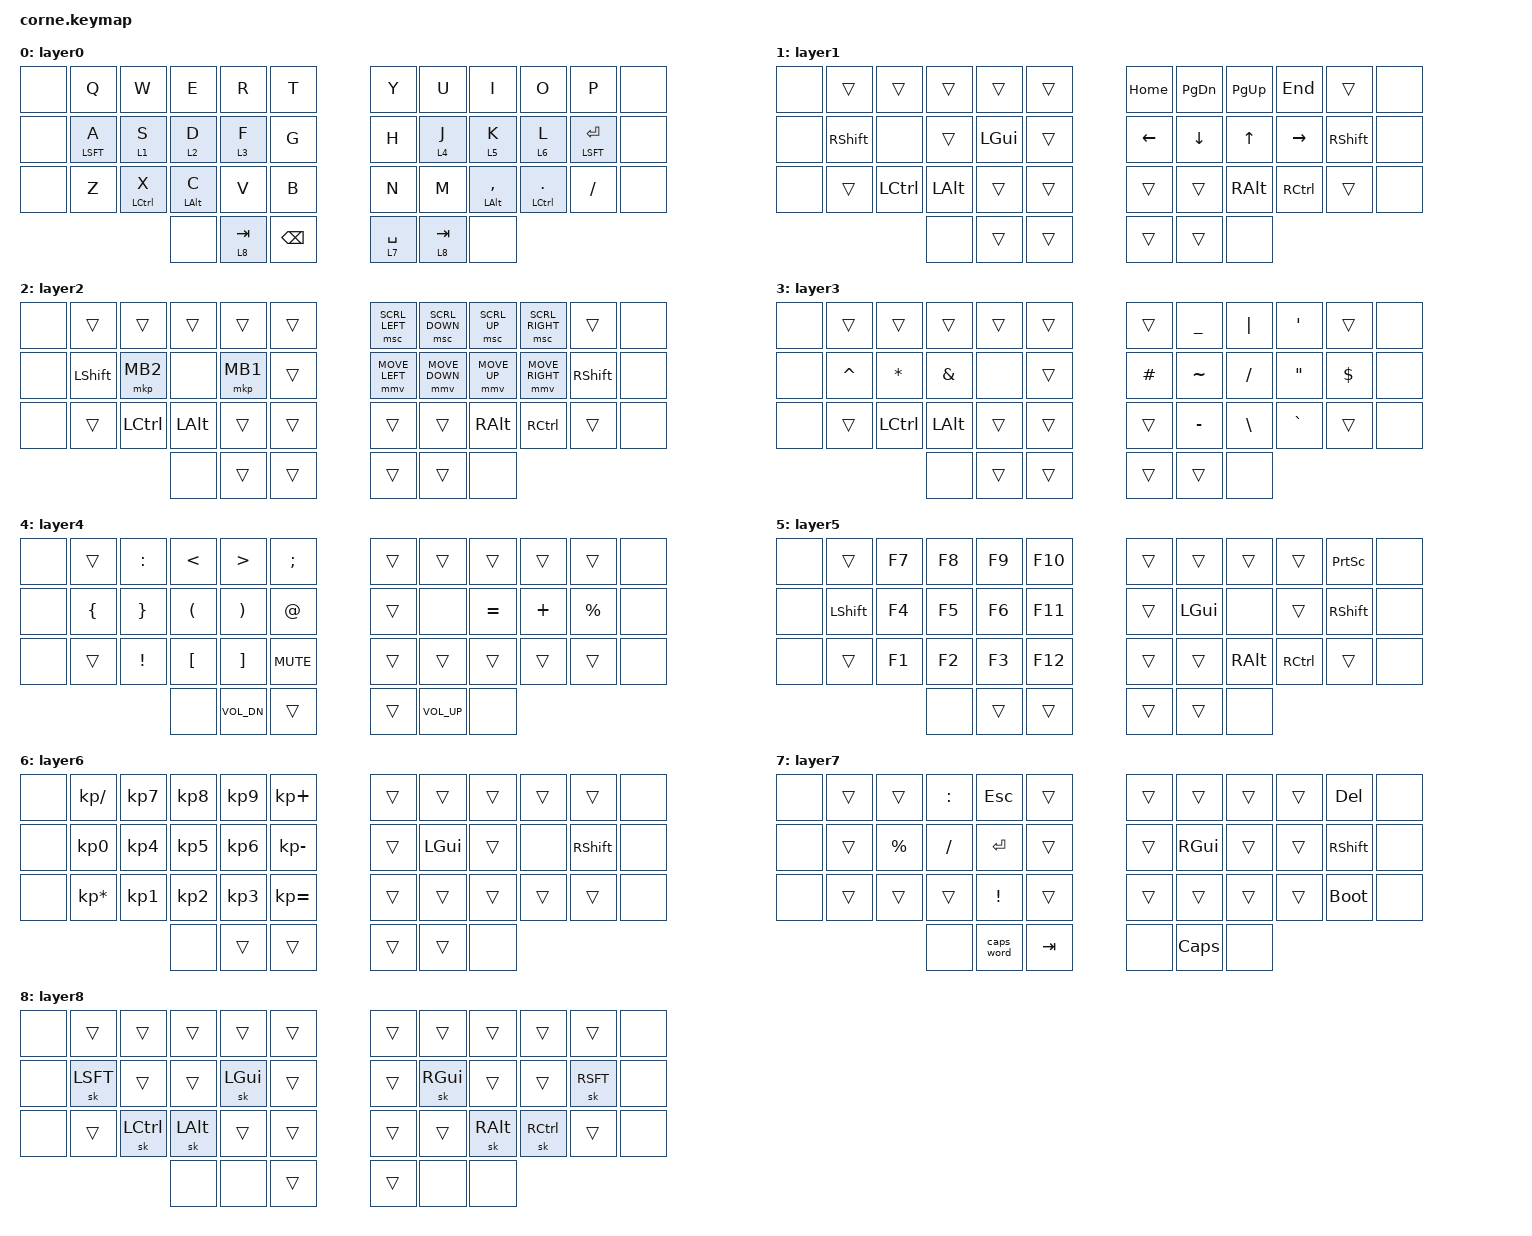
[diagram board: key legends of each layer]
/*
 * Copyright (c) 2020 The ZMK Contributors
 *
 * SPDX-License-Identifier: MIT
 */

#include <behaviors.dtsi>
#include <dt-bindings/zmk/keys.h>
#include <dt-bindings/zmk/bt.h>

#include <dt-bindings/zmk/pointing.h>


/ {
        behaviors {
                ht_bl: balanced_homerow_mods {
                        compatible = "zmk,behavior-hold-tap";
                        #binding-cells = <2>;
                        tapping-term-ms = <200>;    // <---[[moderate duration]]
                        quick-tap-ms = <0>;
                        flavor = "balanced";
                        bindings = <&kp>, <&kp>;

                };
        };
        keymap {
                compatible = "zmk,keymap";
        layer0 {
                bindings = <
&none           &kp Q           &kp W           &kp E           &kp R           &kp T           &kp Y           &kp U           &kp I           &kp O           &kp P           &none
&none           &ht_bl LSFT A   &lt 1 S         &lt 2 D         &lt 3 F         &kp G           &kp H           &lt 4 J         &lt 5 K         &lt 6 L         &ht_bl LSFT ENTER&none
&none           &kp Z           &ht_bl LCTL X   &mt LALT C      &kp V           &kp B           &kp N           &kp M           &mt LALT COMMA  &ht_bl LCTL DOT &kp FSLH        &none
                                                &none           &lt 8 TAB       &kp BSPC        &lt 7 SPC       &lt 8 TAB       &none
                >;
        };
        layer1 {
                bindings = <
&none           &trans          &trans          &trans          &trans          &trans          &kp HOME        &kp PG_DN       &kp PG_UP       &kp END         &trans          &none
&none           &kp RSHFT       &none           &trans          &kp LGUI        &trans          &kp LEFT        &kp DOWN        &kp UP          &kp RIGHT       &kp RSHFT       &none
&none           &trans          &kp LCTL        &kp LALT        &trans          &trans          &trans          &trans          &kp RALT        &kp RCTL        &trans          &none
                                                &none           &trans          &trans          &trans          &trans          &none
                >;
        };
        layer2 {
                bindings = <
&none           &trans          &trans          &trans          &trans          &trans          &msc SCRL_LEFT  &msc SCRL_DOWN  &msc SCRL_UP    &msc SCRL_RIGHT &trans          &none
&none           &kp LSHFT       &mkp MB2        &none           &mkp MB1        &trans          &mmv MOVE_LEFT  &mmv MOVE_DOWN  &mmv MOVE_UP    &mmv MOVE_RIGHT &kp RSHFT       &none
&none           &trans          &kp LCTL        &kp LALT        &trans          &trans          &trans          &trans          &kp RALT        &kp RCTL        &trans          &none
                                                &none           &trans          &trans          &trans          &trans          &none
                >;
        };
        layer3 {
                bindings = <
&none           &trans          &trans          &trans          &trans          &trans          &trans          &kp UNDER       &kp PIPE        &kp SQT         &trans          &none
&none           &kp CARET       &kp STAR        &kp AMPS        &none           &trans          &kp HASH        &kp TILDE       &kp FSLH        &kp DQT         &kp DLLR        &none
&none           &trans          &kp LCTL        &kp LALT        &trans          &trans          &trans          &kp MINUS       &kp BSLH        &kp GRAVE       &trans          &none
                                                &none           &trans          &trans          &trans          &trans          &none
                >;
        };
        layer4 {
                bindings = <
&none           &trans          &kp COLON       &kp LT          &kp GT          &kp SEMI        &trans          &trans          &trans          &trans          &trans          &none
&none           &kp LBRC        &kp RBRC        &kp LPAR        &kp RPAR        &kp AT          &trans          &none           &kp EQUAL       &kp PLUS        &kp PERCENT     &none
&none           &trans          &kp EXCL        &kp LBKT        &kp RBKT        &kp C_MUTE      &trans          &trans          &trans          &trans          &trans          &none
                                                &none           &kp C_VOL_DN    &trans          &trans          &kp C_VOL_UP    &none
                >;
        };
        layer5 {
                bindings = <
&none           &trans          &kp F7          &kp F8          &kp F9          &kp F10         &trans          &trans          &trans          &trans          &kp PSCRN       &none
&none           &kp LSHFT       &kp F4          &kp F5          &kp F6          &kp F11         &trans          &kp LGUI        &none           &trans          &kp RSHFT       &none
&none           &trans          &kp F1          &kp F2          &kp F3          &kp F12         &trans          &trans          &kp RALT        &kp RCTL        &trans          &none
                                                &none           &trans          &trans          &trans          &trans          &none
                >;
        };
        layer6 {
                bindings = <
&none           &kp KP_SLASH    &kp KP_NUMBER_7 &kp KP_NUMBER_8 &kp KP_NUMBER_9 &kp KP_PLUS     &trans          &trans          &trans          &trans          &trans          &none
&none           &kp KP_NUMBER_0 &kp KP_NUMBER_4 &kp KP_NUMBER_5 &kp KP_NUMBER_6 &kp KP_MINUS    &trans          &kp LGUI        &trans          &none           &kp RSHFT       &none
&none           &kp KP_ASTERISK &kp KP_NUMBER_1 &kp KP_NUMBER_2 &kp KP_NUMBER_3 &kp KP_EQUAL    &trans          &trans          &trans          &trans          &trans          &none
                                                &none           &trans          &trans          &trans          &trans          &none
                >;
        };
        layer7 {
                bindings = <
&none           &trans          &trans          &kp COLON       &kp ESC         &trans          &trans          &trans          &trans          &trans          &kp DEL         &none
&none           &trans          &kp PERCENT     &kp FSLH        &kp ENTER       &trans          &trans          &kp RGUI        &trans          &trans          &kp RSHFT       &none
&none           &trans          &trans          &trans          &kp EXCL        &trans          &trans          &trans          &trans          &trans          &bootloader     &none
                                                &none           &caps_word      &kp TAB         &none           &kp CAPS        &none
                >;
        };
        layer8 {
                bindings = <
&none           &trans          &trans          &trans          &trans          &trans          &trans          &trans          &trans          &trans          &trans          &none
&none           &sk LSFT        &trans          &trans          &sk LGUI        &trans          &trans          &sk RGUI        &trans          &trans          &sk RSFT        &none
&none           &trans          &sk LCTL        &sk LALT        &trans          &trans          &trans          &trans          &sk RALT        &sk RCTL        &trans          &none
                                                &none           &none           &trans          &trans          &none           &none
                >;
        };
        };
};

